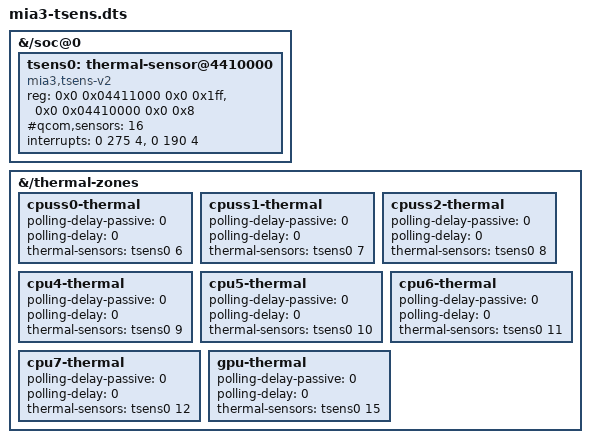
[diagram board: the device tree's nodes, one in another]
/dts-v1/;
/plugin/;
/* TSENS (v2, 16 sensors) from the stock dtb; read-only zones, no trips/cooling.
 * Driver: mia3_tsens.ko (mainline tsens with __init dropped; the built-in one frees its init code after boot).
 * Sensors: 6-8 little cluster (cpuss), 9-12 big cores (cpu4-7), 15 GPU. */
&{/soc@0} {
	tsens0: thermal-sensor@4410000 {
		compatible = "mia3,tsens-v2";
		reg = <0x0 0x04411000 0x0 0x1ff>, <0x0 0x04410000 0x0 0x8>;
		#qcom,sensors = <16>;
		interrupts = <0 275 4>, <0 190 4>;
		interrupt-names = "uplow", "critical";
		#thermal-sensor-cells = <1>;
	};
};
&{/thermal-zones} {
	cpuss0-thermal {
		polling-delay-passive = <0>;
		polling-delay = <0>;
		thermal-sensors = <&tsens0 6>;
	};
	cpuss1-thermal {
		polling-delay-passive = <0>;
		polling-delay = <0>;
		thermal-sensors = <&tsens0 7>;
	};
	cpuss2-thermal {
		polling-delay-passive = <0>;
		polling-delay = <0>;
		thermal-sensors = <&tsens0 8>;
	};
	cpu4-thermal {
		polling-delay-passive = <0>;
		polling-delay = <0>;
		thermal-sensors = <&tsens0 9>;
	};
	cpu5-thermal {
		polling-delay-passive = <0>;
		polling-delay = <0>;
		thermal-sensors = <&tsens0 10>;
	};
	cpu6-thermal {
		polling-delay-passive = <0>;
		polling-delay = <0>;
		thermal-sensors = <&tsens0 11>;
	};
	cpu7-thermal {
		polling-delay-passive = <0>;
		polling-delay = <0>;
		thermal-sensors = <&tsens0 12>;
	};
	gpu-thermal {
		polling-delay-passive = <0>;
		polling-delay = <0>;
		thermal-sensors = <&tsens0 15>;
	};
};
